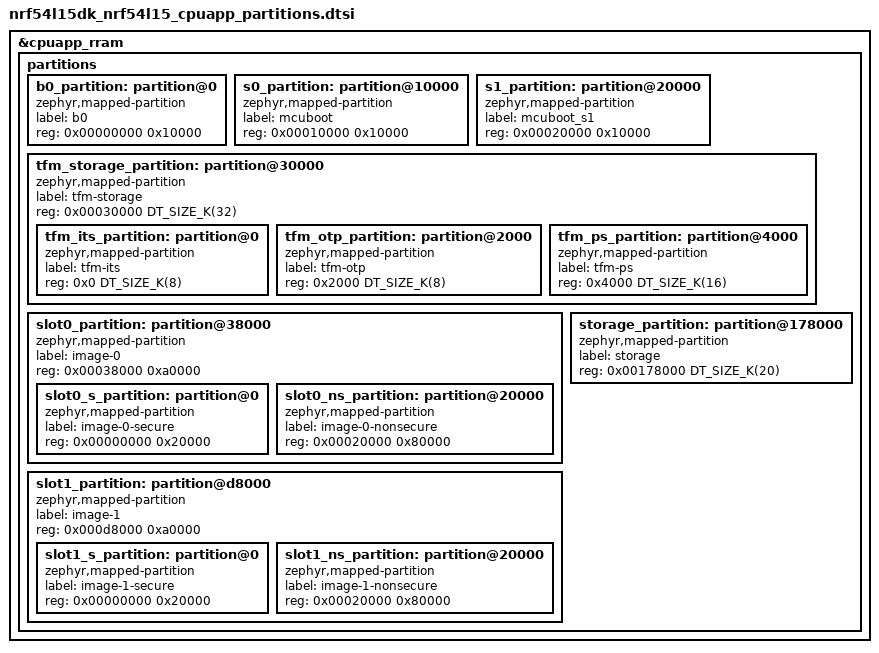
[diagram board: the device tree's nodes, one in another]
/*
 * Copyright (c) 2026 Nordic Semiconductor ASA
 *
 * SPDX-License-Identifier: LicenseRef-Nordic-5-Clause
 */

&cpuapp_rram {
	partitions {
		ranges;
		#address-cells = <1>;
		#size-cells = <1>;

		b0_partition: partition@0 {
			compatible = "zephyr,mapped-partition";
			label = "b0";
			reg = <0x00000000 0x10000>;
		};

		s0_partition: partition@10000 {
			compatible = "zephyr,mapped-partition";
			label = "mcuboot";
			reg = <0x00010000 0x10000>;
		};

		s1_partition: partition@20000 {
			compatible = "zephyr,mapped-partition";
			label = "mcuboot_s1";
			reg = <0x00020000 0x10000>;
		};

		tfm_storage_partition: partition@30000 {
			compatible = "zephyr,mapped-partition";
			label = "tfm-storage";
			reg = <0x00030000 DT_SIZE_K(32)>;
			ranges = <0x0 0x00030000 DT_SIZE_K(32)>;
			#address-cells = <1>;
			#size-cells = <1>;

			tfm_its_partition: partition@0 {
				compatible = "zephyr,mapped-partition";
				label = "tfm-its";
				reg = <0x0 DT_SIZE_K(8)>;
			};

			tfm_otp_partition: partition@2000 {
				compatible = "zephyr,mapped-partition";
				label = "tfm-otp";
				reg = <0x2000 DT_SIZE_K(8)>;
			};

			tfm_ps_partition: partition@4000 {
				compatible = "zephyr,mapped-partition";
				label = "tfm-ps";
				reg = <0x4000 DT_SIZE_K(16)>;
			};
		};

		slot0_partition: partition@38000 {
			compatible = "zephyr,mapped-partition";
			label = "image-0";
			reg = <0x00038000 0xa0000>;
			ranges = <0x0 0x00038000 0xa0000>;
			#address-cells = <1>;
			#size-cells = <1>;

			slot0_s_partition: partition@0 {
				compatible = "zephyr,mapped-partition";
				label = "image-0-secure";
				reg = <0x00000000 0x20000>;
			};

			slot0_ns_partition: partition@20000 {
				compatible = "zephyr,mapped-partition";
				label = "image-0-nonsecure";
				reg = <0x00020000 0x80000>;
			};
		};

		slot1_partition: partition@d8000 {
			compatible = "zephyr,mapped-partition";
			label = "image-1";
			reg = <0x000d8000 0xa0000>;
			ranges = <0x0 0x000d8000 0xa0000>;
			#address-cells = <1>;
			#size-cells = <1>;

			slot1_s_partition: partition@0 {
				compatible = "zephyr,mapped-partition";
				label = "image-1-secure";
				reg = <0x00000000 0x20000>;
			};

			slot1_ns_partition: partition@20000 {
				compatible = "zephyr,mapped-partition";
				label = "image-1-nonsecure";
				reg = <0x00020000 0x80000>;
			};
		};

		storage_partition: partition@178000 {
			compatible = "zephyr,mapped-partition";
			label = "storage";
			reg = <0x00178000 DT_SIZE_K(20)>;
		};
	};
};
